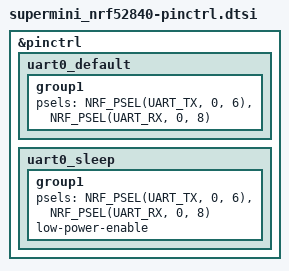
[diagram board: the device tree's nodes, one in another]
/*
 * Pin control for SuperMini nRF52840.
 * UART0: TX=P0.06, RX=P0.08 (matches Nice!Nano v2 D0/D1 header pins).
 */

&pinctrl {
	uart0_default: uart0_default {
		group1 {
			psels = <NRF_PSEL(UART_TX, 0, 6)>,
				<NRF_PSEL(UART_RX, 0, 8)>;
		};
	};

	uart0_sleep: uart0_sleep {
		group1 {
			psels = <NRF_PSEL(UART_TX, 0, 6)>,
				<NRF_PSEL(UART_RX, 0, 8)>;
			low-power-enable;
		};
	};
};
